# MDR1986VK01 register map
File version: 1.0.2
Registers are 32-bit, read-write, no defined reset value unless marked. A register's access mark holds for its fields unless they carry their own. Offsets are from the block's base; [hi:lo] are bit positions; {n}, {i} and the like mark numbered series.

## MDR_USB_TAR2 — MDR_USB_TAR2 description
Base 0x2101008C
0x00 TX_FUNC_ADDR_T2 8-bit — TX_FUNC_ADDR_T2 description
0x02 TX_HUD_ADDR_T2 8-bit — TX_HUD_ADDR_T2 description
0x03 TX_HUD_PORT_T2 8-bit — TX_HUD_PORT_T2 description
0x04 RX_FUNC_ADDR_T2 8-bit — RX_FUNC_ADDR_T2 description
0x06 RX_HUD_ADDR_T2 8-bit — RX_HUD_ADDR_T2 description
0x07 RX_HUD_PORT_T2 8-bit — RX_HUD_PORT_T2 description

## MDR_USB_TAR3 — MDR_USB_TAR3 description
Base 0x21010094
0x00 TX_FUNC_ADDR_T3 8-bit — TX_FUNC_ADDR_T3 description
0x02 TX_HUD_ADDR_T3 8-bit — TX_HUD_ADDR_T3 description
0x03 TX_HUD_PORT_T3 8-bit — TX_HUD_PORT_T3 description
0x04 RX_FUNC_ADDR_T3 8-bit — RX_FUNC_ADDR_T3 description
0x06 RX_HUD_ADDR_T3 8-bit — RX_HUD_ADDR_T3 description
0x07 RX_HUD_PORT_T3 8-bit — RX_HUD_PORT_T3 description

## MDR_FTMODE — MDR_FTMODE description
Base 0x40003000
0x00 KEY — KEY description
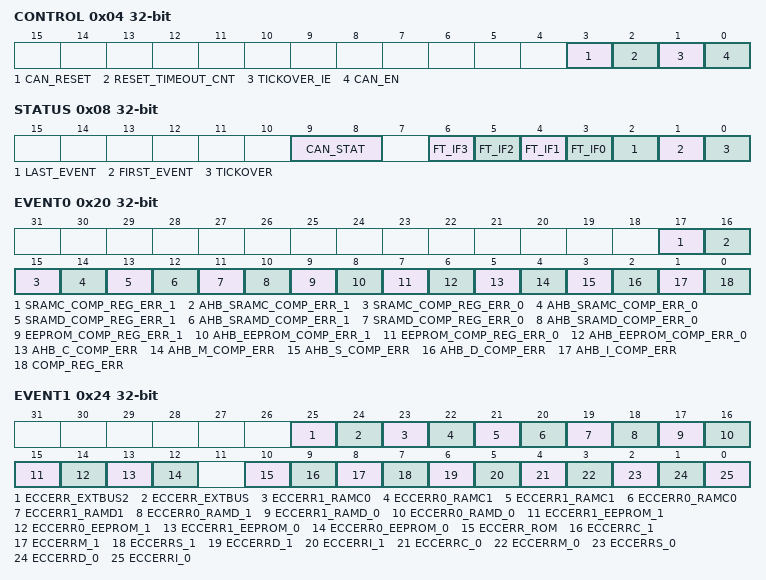
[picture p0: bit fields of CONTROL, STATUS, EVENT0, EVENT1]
0x04 CONTROL — CONTROL description
  [3] CAN_RESET — CAN_RESET description
  [2] RESET_TIMEOUT_CNT — RESET_TIMEOUT_CNT description
  [1] TICKOVER_IE — TICKOVER_IE description
  [0] CAN_EN — CAN_EN description
0x08 STATUS — STATUS description
  [9:8] CAN_STAT — CAN_STAT description
  [n+3] FT_IF{n} (n=0..3) — FT_IF{n} description
  [2] LAST_EVENT — LAST_EVENT description
  [1] FIRST_EVENT — FIRST_EVENT description
  [0] TICKOVER — TICKOVER description
0x0C TIMEOUT — TIMEOUT description
  [15:0] TIMEOUT
0x10 TICKCNT — TICKCNT description
0x14 FIRSTEVENT — FIRSTEVENT description
0x18 LASTEVENT — LASTEVENT description
0x1C TIMEOUTCNT — TIMEOUTCNT description
  [16:0] TIMEOUTCNT
0x20 EVENT0 — EVENT0 description
  [17] SRAMC_COMP_REG_ERR_1 — SRAMC_COMP_REG_ERR_1 description
  [16] AHB_SRAMC_COMP_ERR_1 — AHB_SRAMC_COMP_ERR_1 description
  [15] SRAMC_COMP_REG_ERR_0 — SRAMC_COMP_REG_ERR_0 description
  [14] AHB_SRAMC_COMP_ERR_0 — AHB_SRAMC_COMP_ERR_0 description
  [13] SRAMD_COMP_REG_ERR_1 — SRAMD_COMP_REG_ERR_1 description
  [12] AHB_SRAMD_COMP_ERR_1 — AHB_SRAMD_COMP_ERR_1 description
  [11] SRAMD_COMP_REG_ERR_0 — SRAMD_COMP_REG_ERR_0 description
  [10] AHB_SRAMD_COMP_ERR_0 — AHB_SRAMD_COMP_ERR_0 description
  [9] EEPROM_COMP_REG_ERR_1 — EEPROM_COMP_REG_ERR_1 description
  [8] AHB_EEPROM_COMP_ERR_1 — AHB_EEPROM_COMP_ERR_1 description
  [7] EEPROM_COMP_REG_ERR_0 — EEPROM_COMP_REG_ERR_0 description
  [6] AHB_EEPROM_COMP_ERR_0 — AHB_EEPROM_COMP_ERR_0 description
  [5] AHB_C_COMP_ERR — AHB_C_COMP_ERR description
  [4] AHB_M_COMP_ERR — AHB_M_COMP_ERR description
  [3] AHB_S_COMP_ERR — AHB_S_COMP_ERR description
  [2] AHB_D_COMP_ERR — AHB_D_COMP_ERR description
  [1] AHB_I_COMP_ERR — AHB_I_COMP_ERR description
  [0] COMP_REG_ERR — COMP_REG_ERR description
0x24 EVENT1 — EVENT1 description
  [25] ECCERR_EXTBUS2 — ECCERR_EXTBUS2 description
  [24] ECCERR_EXTBUS — ECCERR_EXTBUS description
  [23] ECCERR1_RAMC0 — ECCERR1_RAMC0 description
  [22] ECCERR0_RAMC1 — ECCERR0_RAMC1 description
  [21] ECCERR1_RAMC1 — ECCERR1_RAMC1 description
  [20] ECCERR0_RAMC0 — ECCERR0_RAMC0 description
  [19] ECCERR1_RAMD1 — ECCERR1_RAMD1 description
  [18] ECCERR0_RAMD_1 — ECCERR0_RAMD_1 description
  [17] ECCERR1_RAMD_0 — ECCERR1_RAMD_0 description
  [16] ECCERR0_RAMD_0 — ECCERR0_RAMD_0 description
  [15] ECCERR1_EEPROM_1 — ECCERR1_EEPROM_1 description
  [14] ECCERR0_EEPROM_1 — ECCERR0_EEPROM_1 description
  [13] ECCERR1_EEPROM_0 — ECCERR1_EEPROM_0 description
  [12] ECCERR0_EEPROM_0 — ECCERR0_EEPROM_0 description
  [10] ECCERR_ROM — ECCERR_ROM description
  [9] ECCERRC_1 — ECCERRC_1 description
  [8] ECCERRM_1 — ECCERRM_1 description
  [7] ECCERRS_1 — ECCERRS_1 description
  [6] ECCERRD_1 — ECCERRD_1 description
  [5] ECCERRI_1 — ECCERRI_1 description
  [4] ECCERRC_0 — ECCERRC_0 description
  [3] ECCERRM_0 — ECCERRM_0 description
  [2] ECCERRS_0 — ECCERRS_0 description
  [1] ECCERRD_0 — ECCERRD_0 description
  [0] ECCERRI_0 — ECCERRI_0 description
{0x20+4i} EVENT{i} (i=2..12) — EVENT{i} description
{0x54+4i} RESET_EVENT{i} (i=0..4) — RESET_EVENT{i} description
{0x54+4i} IE_EVENT{i} (i=5..12) — IE_EVENT{i} description
0x88 STAT0 — STAT0 description
0x8C STAT1 — STAT1 description
